# AT91SAM9M11 register map
Vendor: Atmel; File version: 20130207
CPU: 
Registers are 32-bit, read-write, no defined reset value unless marked. A register's access mark holds for its fields unless they carry their own. Offsets are from the block's base; [hi:lo] are bit positions; {n}, {i} and the like mark numbered series.

## AES — Advanced Encryption Standard
Base 0xFFFC0000; register names take the prefix AES_
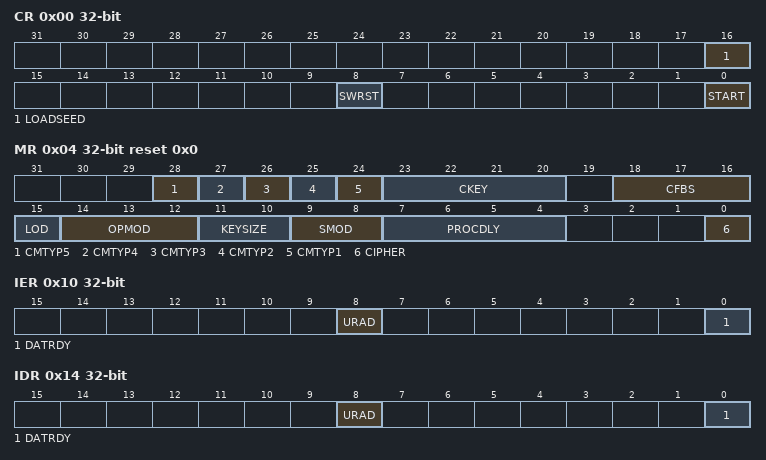
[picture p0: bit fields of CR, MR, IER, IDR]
0x00 CR wo — Control Register
  [16] LOADSEED — Random Number Generator Seed Loading
  [8] SWRST — Software Reset
  [0] START — Start Processing
0x04 MR reset 0x0 — Mode Register
  [28] CMTYP5 — CounterMeasure Type 5
    0=NO_ADDACCESS (Counter-Measure type 5 is disabled); 1=ADDACCESS (Counter-Measure type 5 is enabled)
  [27] CMTYP4 — CounterMeasure Type 4
    0=NO_RESTART (Counter-Measure type 4 is disabled); 1=RESTART (Counter-Measure type 4 is enabled)
  [26] CMTYP3 — CounterMeasure Type 3
    0=NO_DUMMY (Counter-Measure type 3 is disabled); 1=DUMMY (Counter-Measure type 3 is enabled)
  [25] CMTYP2 — CounterMeasure Type 2
    0=NO_PAUSE (Counter-Measure type 2 is disabled); 1=PAUSE (Counter-Measure type 2 is enabled)
  [24] CMTYP1 — CounterMeasure Type 1
    0=NOPROT_EXTXKEY (Counter-Measure type 1 is disabled); 1=PROT_EXTKEY (Counter-Measure type 1 is enabled)
  [23:20] CKEY — Countermeasure Key
  [18:16] CFBS — Cipher Feedback Data Size
    0=SIZE_128BIT (128-bit); 1=SIZE_64BIT (64-bit); 2=SIZE_32BIT (32-bit); 3=SIZE_16BIT (16-bit); 4=SIZE_8BIT (8-bit)
  [15] LOD — Last Output Data Mode
  [14:12] OPMOD — Operation Mode
    0=ECB (ECB: Electronic Code Book mode); 1=CBC (CBC: Cipher Block Chaining mode); 2=OFB (OFB: Output Feedback mode); 3=CFB (CFB: Cipher Feedback mode); 4=CTR (CTR: Counter mode (16-bit internal counter))
  [11:10] KEYSIZE
    0=AES128 (AES Key Size is 128 bits); 1=AES192 (AES Key Size is 192 bits); 2=AES256 (AES Key Size is 256 bits)
  [9:8] SMOD — Start Mode
    0=MANUAL_START (Manual Mode); 1=AUTO_START (Auto Mode); 2=IDATAR0_START (AES_IDATAR0 access only Auto Mode)
  [7:4] PROCDLY — Processing Delay
  [0] CIPHER — Processing Mode
0x10 IER wo — Interrupt Enable Register
  [8] URAD — Unspecified Register Access Detection Interrupt Enable
  [0] DATRDY — Data Ready Interrupt Enable
0x14 IDR wo — Interrupt Disable Register
  [8] URAD — Unspecified Register Access Detection Interrupt Disable
  [0] DATRDY — Data Ready Interrupt Disable
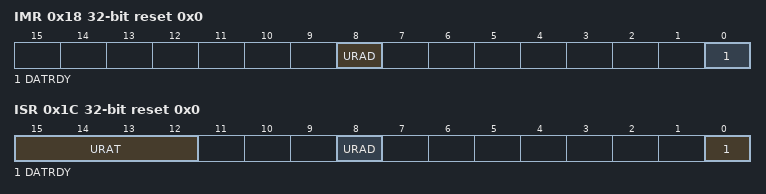
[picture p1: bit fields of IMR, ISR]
0x18 IMR ro reset 0x0 — Interrupt Mask Register
  [8] URAD — Unspecified Register Access Detection Interrupt Mask
  [0] DATRDY — Data Ready Interrupt Mask
0x1C ISR ro reset 0x0 — Interrupt Status Register
  [15:12] URAT — Unspecified Register Access Type:
    0=IDR_WR_PROCESSING (Input Data Register written during the data processing when SMOD=0x2 mode.); 1=ODR_RD_PROCESSING (Output Data Register read during the data processing.); 2=MR_WR_PROCESSING (Mode Register written during the data processing.); 3=ODR_RD_SUBKGEN (Output Data Register read during the sub-keys generation.); 4=MR_WR_SUBKGEN (Mode Register written during the sub-keys generation.); 5=WOR_RD_ACCESS (Write-only register read access.)
  [8] URAD — Unspecified Register Access Detection Status
  [0] DATRDY — Data Ready
{0x20+4i} KEYWR[{i}] wo (i=0..7) — Key Word Register
  [31:0] KEYW — Key Word
{0x40+4i} IDATAR[{i}] wo (i=0..3) — Input Data Register
  [31:0] IDATA — Input Data Word
{0x50+4i} ODATAR[{i}] ro (i=0..3) — Output Data Register
  [31:0] ODATA — Output Data
{0x60+4i} IVR[{i}] wo (i=0..3) — Initialization Vector Register
  [31:0] IV — Initialization Vector

## TDES — Triple Data Encryption Standard
Base 0xFFFC4000; register names take the prefix TDES_
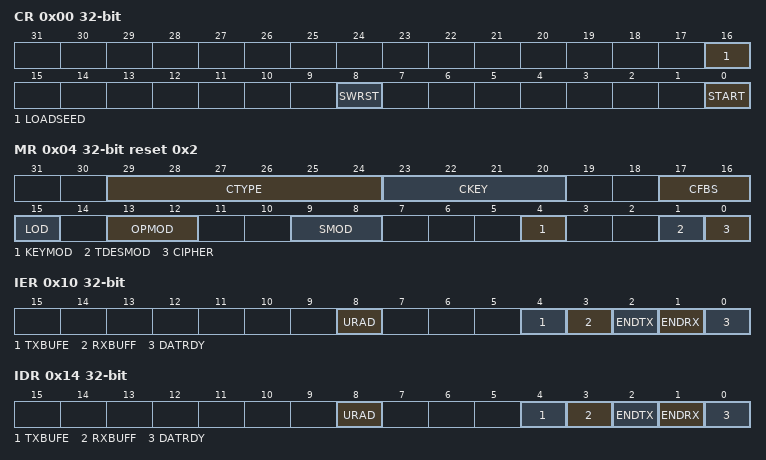
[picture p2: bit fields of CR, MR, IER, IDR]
0x00 CR wo — Control Register
  [16] LOADSEED
  [8] SWRST — Software Reset
  [0] START — Start Processing
0x04 MR reset 0x2 — Mode Register
  [29:24] CTYPE — Countermeasure Type
  [23:20] CKEY — Countermeasure Key
  [17:16] CFBS — Cipher Feedback Data Size
  [15] LOD — Last Output Data Mode
  [13:12] OPMOD — Operation Mode
  [9:8] SMOD — Start Mode
  [4] KEYMOD — Key Mode
  [1] TDESMOD — ALGORITHM mode
  [0] CIPHER — Processing Mode
0x10 IER wo — Interrupt Enable Register
  [8] URAD — Unspecified Register Access Detection Interrupt Enable
  [4] TXBUFE — Transmit Buffer Empty Interrupt Enable
  [3] RXBUFF — Receive Buffer Full Interrupt Enable
  [2] ENDTX — End of Transmit Buffer Interrupt Enable
  [1] ENDRX — End of Receive Buffer Interrupt Enable
  [0] DATRDY — Data Ready Interrupt Enable
0x14 IDR wo — Interrupt Disable Register
  [8] URAD — Unspecified Register Access Detection Interrupt Disable
  [4] TXBUFE — Transmit Buffer Empty Interrupt Disable
  [3] RXBUFF — Receive Buffer Full Interrupt Disable
  [2] ENDTX — End of Transmit Buffer Interrupt Disable
  [1] ENDRX — End of Receive Buffer Interrupt Disable
  [0] DATRDY — Data Ready Interrupt Disable
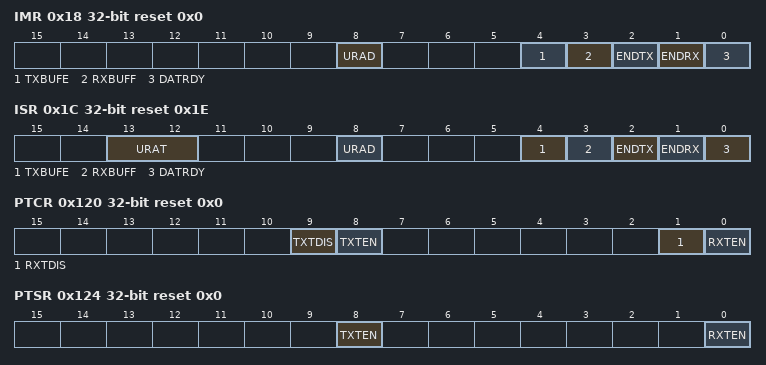
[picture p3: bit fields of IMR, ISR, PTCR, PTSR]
0x18 IMR ro reset 0x0 — Interrupt Mask Register
  [8] URAD — Unspecified Register Access Detection Interrupt Mask
  [4] TXBUFE — Transmit Buffer Empty Interrupt Mask
  [3] RXBUFF — Receive Buffer Full Interrupt Mask
  [2] ENDTX — End of Transmit Buffer Interrupt Mask
  [1] ENDRX — End of Receive Buffer Interrupt Mask
  [0] DATRDY — Data Ready Interrupt Mask
0x1C ISR ro reset 0x1E — Interrupt Status Register
  [13:12] URAT — Unspecified Register Access Type:
  [8] URAD — Unspecified Register Access Detection Status
  [4] TXBUFE — TX Buffer Empty
  [3] RXBUFF — RX Buffer Full
  [2] ENDTX — End of TX Buffer
  [1] ENDRX — End of RX Buffer
  [0] DATRDY — Data Ready
{0x18+8i} KEY{i}WxR[0] wo (i=1..3) — Key {i} Word Register
  [31:0] KEY{i}Wx — Key {i} Word x
{0x1C+8i} KEY{i}WxR[1] wo (i=1..3) — Key {i} Word Register
  [31:0] KEY{i}Wx — Key {i} Word x
0x40 IDATAxR[0] wo — Input Data Register
  [31:0] IDATAx — Input Data x
0x44 IDATAxR[1] wo — Input Data Register
  [31:0] IDATAx — Input Data x
0x50 ODATAxR[0] ro — Output Data Register
  [31:0] ODATAx — Output Data x
0x54 ODATAxR[1] ro — Output Data Register
  [31:0] ODATAx — Output Data x
0x60 IVxR[0] wo — Initialization Vector Register
  [31:0] IVx — Initialization Vector x
0x64 IVxR[1] wo — Initialization Vector Register
  [31:0] IVx — Initialization Vector x
0x100 RPR reset 0x0 — Receive Pointer Register
  [31:0] RXPTR
0x104 RCR reset 0x0 — Receive Counter Register
  [15:0] RXCTR
0x108 TPR reset 0x0 — Transmit Pointer Register
  [31:0] TXPTR — Transmit Counter Register
0x10C TCR reset 0x0 — Transmit Counter Register
  [15:0] TXCTR
0x110 RNPR reset 0x0 — Receive Next Pointer Register
  [31:0] RXNPTR — Receive Next Pointer
0x114 RNCR reset 0x0 — Receive Next Counter Register
  [15:0] RXNCTR — Receive Next Counter
0x118 TNPR reset 0x0 — Transmit Next Pointer Register
  [31:0] TXNPTR — Transmit Next Pointer
0x11C TNCR reset 0x0 — Transmit Next Counter Register
  [15:0] TXNCTR — Transmit Counter Next
0x120 PTCR wo reset 0x0 — Transfer Control Register
  [9] TXTDIS — Transmitter Transfer Disable
  [8] TXTEN — Transmitter Transfer Enable
  [1] RXTDIS — Receiver Transfer Disable
  [0] RXTEN — Receiver Transfer Enable
0x124 PTSR ro reset 0x0 — Transfer Status Register
  [8] TXTEN — Transmitter Transfer Enable
  [0] RXTEN — Receiver Transfer Enable
